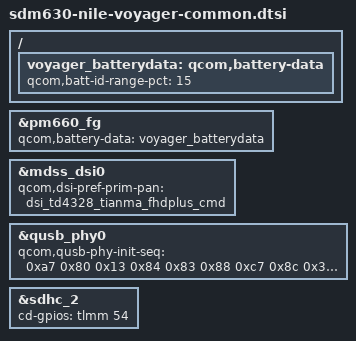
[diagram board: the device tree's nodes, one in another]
/* Copyright (c) 2017, The Linux Foundation. All rights reserved.
 *
 * This program is free software; you can redistribute it and/or modify
 * it under the terms of the GNU General Public License version 2 and
 * only version 2 as published by the Free Software Foundation.
 *
 * This program is distributed in the hope that it will be useful,
 * but WITHOUT ANY WARRANTY; without even the implied warranty of
 * MERCHANTABILITY or FITNESS FOR A PARTICULAR PURPOSE.  See the
 * GNU General Public License for more details.
 */

/ {
	voyager_batterydata: qcom,battery-data {
		qcom,batt-id-range-pct = <15>;
		#include "fg-gen3-batterydata-3450mah.dtsi"
	};
};

&pm660_fg {
	qcom,battery-data = <&voyager_batterydata>;
};

&mdss_dsi0 {
	qcom,dsi-pref-prim-pan = <&dsi_td4328_tianma_fhdplus_cmd>;
};

&qusb_phy0 {
	qcom,qusb-phy-init-seq = <0xa7 0x80
				  0x13 0x84
				  0x83 0x88
				  0xc7 0x8c
				  0x30 0x08
				  0x79 0x0c
				  0x21 0x10
				  0x14 0x9c
				  0x9f 0x1c
				  0x00 0x18
				  0x01 0x90>;
};

&sdhc_2 {
       cd-gpios = <&tlmm 54 0x0>;
};
